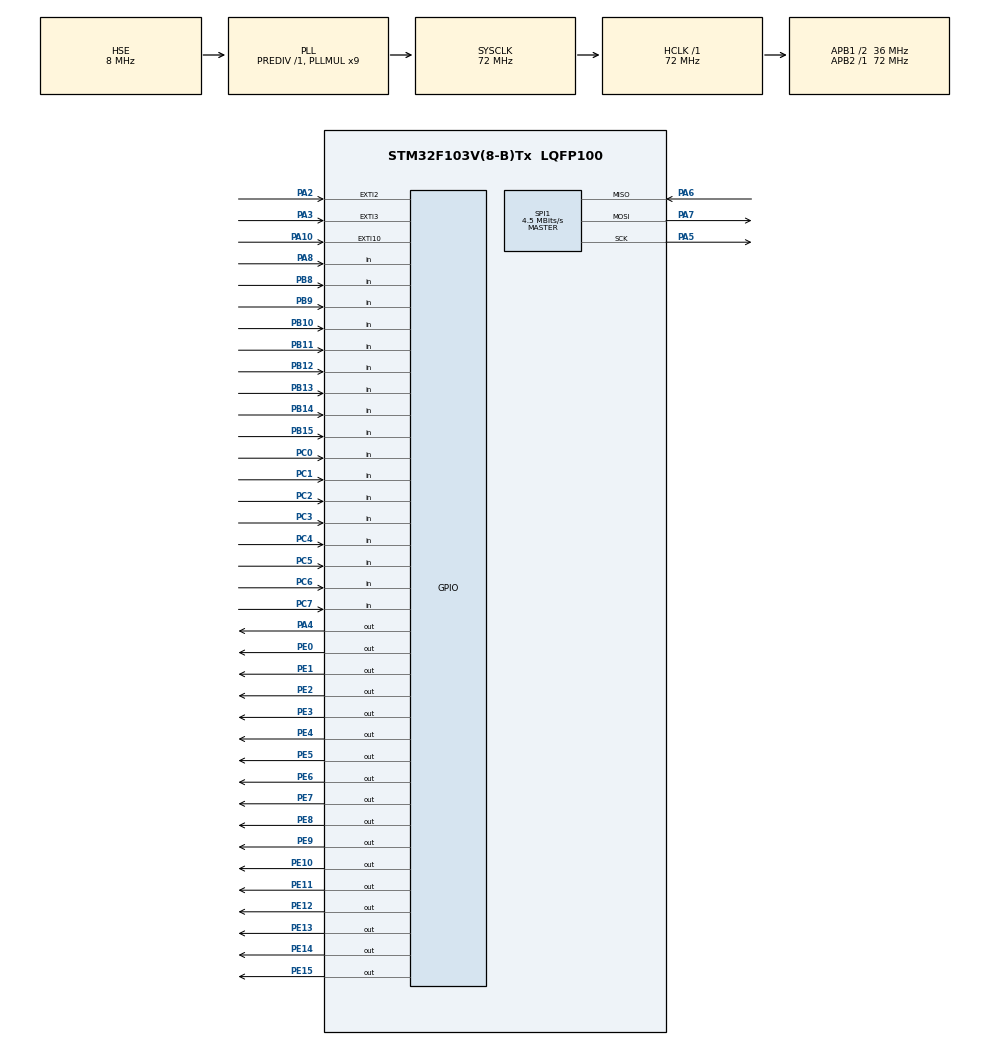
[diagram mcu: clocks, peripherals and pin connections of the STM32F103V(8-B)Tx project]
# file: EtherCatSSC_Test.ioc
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Mcu.Family=STM32F1
Mcu.Name=STM32F103V(8-B)Tx
Mcu.Package=LQFP100
NVIC.PriorityGroup=NVIC_PRIORITYGROUP_4
OSC_IN.Mode=HSE-External-Oscillator
OSC_IN.Signal=RCC_OSC_IN
OSC_OUT.Mode=HSE-External-Oscillator
OSC_OUT.Signal=RCC_OSC_OUT
PA10.Signal=GPXTI10
PA13.Mode=Serial_Wire
PA13.Signal=SYS_JTMS-SWDIO
PA14.Mode=Serial_Wire
PA14.Signal=SYS_JTCK-SWCLK
PA2.Signal=GPXTI2
PA3.Signal=GPXTI3
PA4.GPIO_Speed=GPIO_SPEED_FREQ_HIGH
PA4.PinState=GPIO_PIN_SET
PA4.Signal=GPIO_Output
PA5.Mode=Full_Duplex_Master
PA5.Signal=SPI1_SCK
PA6.Mode=Full_Duplex_Master
PA6.Signal=SPI1_MISO
PA7.Mode=Full_Duplex_Master
PA7.Signal=SPI1_MOSI
PA8.Signal=GPIO_Input
PB10.GPIO_Mode=GPIO_MODE_INPUT
PB10.GPIO_PuPd=GPIO_PULLDOWN
PB10.Signal=GPIO_Input
PB11.GPIO_Mode=GPIO_MODE_INPUT
PB11.GPIO_PuPd=GPIO_PULLDOWN
PB11.Signal=GPIO_Input
PB12.GPIO_Mode=GPIO_MODE_INPUT
PB12.GPIO_PuPd=GPIO_PULLDOWN
PB12.Signal=GPIO_Input
PB13.GPIO_Mode=GPIO_MODE_INPUT
PB13.GPIO_PuPd=GPIO_PULLDOWN
PB13.Signal=GPIO_Input
PB14.GPIO_Mode=GPIO_MODE_INPUT
PB14.GPIO_PuPd=GPIO_PULLDOWN
PB14.Signal=GPIO_Input
PB15.GPIO_Mode=GPIO_MODE_INPUT
PB15.GPIO_PuPd=GPIO_PULLDOWN
PB15.Signal=GPIO_Input
PB8.GPIO_Mode=GPIO_MODE_INPUT
PB8.GPIO_PuPd=GPIO_PULLDOWN
PB8.Signal=GPIO_Input
PB9.GPIO_Mode=GPIO_MODE_INPUT
PB9.GPIO_PuPd=GPIO_PULLDOWN
PB9.Signal=GPIO_Input
PC0.GPIO_Mode=GPIO_MODE_INPUT
PC0.GPIO_PuPd=GPIO_PULLDOWN
PC0.Signal=GPIO_Input
PC1.GPIO_Mode=GPIO_MODE_INPUT
PC1.GPIO_PuPd=GPIO_PULLDOWN
PC1.Signal=GPIO_Input
PC14-OSC32_IN.Mode=LSE-External-Oscillator
PC14-OSC32_IN.Signal=RCC_OSC32_IN
PC15-OSC32_OUT.Mode=LSE-External-Oscillator
PC15-OSC32_OUT.Signal=RCC_OSC32_OUT
PC2.GPIO_Mode=GPIO_MODE_INPUT
PC2.GPIO_PuPd=GPIO_PULLDOWN
PC2.Signal=GPIO_Input
PC3.GPIO_Mode=GPIO_MODE_INPUT
PC3.GPIO_PuPd=GPIO_PULLDOWN
PC3.Signal=GPIO_Input
PC4.GPIO_Mode=GPIO_MODE_INPUT
PC4.GPIO_PuPd=GPIO_PULLDOWN
PC4.Signal=GPIO_Input
PC5.GPIO_Mode=GPIO_MODE_INPUT
PC5.GPIO_PuPd=GPIO_PULLDOWN
PC5.Signal=GPIO_Input
PC6.GPIO_Mode=GPIO_MODE_INPUT
PC6.GPIO_PuPd=GPIO_PULLDOWN
PC6.Signal=GPIO_Input
PC7.GPIO_Mode=GPIO_MODE_INPUT
PC7.GPIO_PuPd=GPIO_PULLDOWN
PC7.Signal=GPIO_Input
PE0.Signal=GPIO_Output
PE1.Signal=GPIO_Output
PE10.Signal=GPIO_Output
PE11.Signal=GPIO_Output
PE12.Signal=GPIO_Output
PE13.Signal=GPIO_Output
PE14.Signal=GPIO_Output
PE15.Signal=GPIO_Output
PE2.Signal=GPIO_Output
PE3.Signal=GPIO_Output
PE4.Signal=GPIO_Output
PE5.Signal=GPIO_Output
PE6.Signal=GPIO_Output
PE7.Signal=GPIO_Output
PE8.Signal=GPIO_Output
PE9.Signal=GPIO_Output
ProjectManager.HeapSize=0x200
ProjectManager.StackSize=0x400
ProjectManager.TargetToolchain=MDK-ARM V5.32
RCC.AHBFreq_Value=72000000
RCC.APB1CLKDivider=RCC_HCLK_DIV2
RCC.APB1Freq_Value=36000000
RCC.APB1TimFreq_Value=72000000
RCC.APB2Freq_Value=72000000
RCC.APB2TimFreq_Value=72000000
RCC.HCLKFreq_Value=72000000
RCC.PLLMUL=RCC_PLL_MUL9
RCC.PLLSourceVirtual=RCC_PLLSOURCE_HSE
RCC.SYSCLKFreq_VALUE=72000000
RCC.SYSCLKSource=RCC_SYSCLKSOURCE_PLLCLK
RCC.USBFreq_Value=72000000
SPI1.BaudRatePrescaler=SPI_BAUDRATEPRESCALER_16
SPI1.CLKPhase=SPI_PHASE_2EDGE
SPI1.CLKPolarity=SPI_POLARITY_HIGH
SPI1.CalculateBaudRate=4.5 MBits/s
SPI1.Direction=SPI_DIRECTION_2LINES
SPI1.Mode=SPI_MODE_MASTER
SPI1.VirtualType=VM_MASTER
board=custom

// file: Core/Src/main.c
/* USER CODE BEGIN Header */
/**
  ******************************************************************************
  * @file           : main.c
  * @brief          : Main program body
  ******************************************************************************
  * @attention
  *
  * Copyright (c) 2026 STMicroelectronics.
  * All rights reserved.
  *
  * This software is licensed under terms that can be found in the LICENSE file
  * in the root directory of this software component.
  * If no LICENSE file comes with this software, it is provided AS-IS.
  *
  ******************************************************************************
  */
/* USER CODE END Header */
#include "main.h"
#include "spi.h"
#include "gpio.h"

/* USER CODE BEGIN Includes */
#include "AX58100.h"
#include "Esc_hw.h"
#include "applInterface.h"
/* USER CODE END Includes */

/* USER CODE BEGIN PD */
#ifndef AX58100_SELF_TEST_ENABLE
#define AX58100_SELF_TEST_ENABLE  0
#endif

/* USER CODE END PD */

void SystemClock_Config(void);

int main(void)
{

  /* MCU Configuration--------------------------------------------------------*/

  /* Reset of all peripherals, Initializes the Flash interface and the Systick. */
  HAL_Init();

  /* Configure the system clock */
  SystemClock_Config();

  /* Initialize all configured peripherals */
  MX_GPIO_Init();
  MX_SPI1_Init();
  /* USER CODE BEGIN 2 */
  // 等待AX58100就绪，否则无法正常进入OP
  if (!AX58100_WaitReady(3000))
  {
      while (1)
      {
          /* AX58100 not ready */
      }
  }

  #if AX58100_SELF_TEST_ENABLE
  AX58100_SelfTest();
  #endif
  MainInit();
  /* USER CODE END 2 */

  /* Infinite loop */
  /* USER CODE BEGIN WHILE */
  while (1)
  {
    MainLoop();
    /* USER CODE END WHILE */

  }
}

void SystemClock_Config(void)
{
  RCC_OscInitTypeDef RCC_OscInitStruct = {0};
  RCC_ClkInitTypeDef RCC_ClkInitStruct = {0};

  /** Initializes the RCC Oscillators according to the specified parameters
  * in the RCC_OscInitTypeDef structure.
  */
  RCC_OscInitStruct.OscillatorType = RCC_OSCILLATORTYPE_HSE;
  RCC_OscInitStruct.HSEState = RCC_HSE_ON;
  RCC_OscInitStruct.HSEPredivValue = RCC_HSE_PREDIV_DIV1;
  RCC_OscInitStruct.HSIState = RCC_HSI_ON;
  RCC_OscInitStruct.PLL.PLLState = RCC_PLL_ON;
  RCC_OscInitStruct.PLL.PLLSource = RCC_PLLSOURCE_HSE;
  RCC_OscInitStruct.PLL.PLLMUL = RCC_PLL_MUL9;
  if (HAL_RCC_OscConfig(&RCC_OscInitStruct) != HAL_OK)
  {
    Error_Handler();
  }

  /** Initializes the CPU, AHB and APB buses clocks
  */
  RCC_ClkInitStruct.ClockType = RCC_CLOCKTYPE_HCLK|RCC_CLOCKTYPE_SYSCLK
                              |RCC_CLOCKTYPE_PCLK1|RCC_CLOCKTYPE_PCLK2;
  RCC_ClkInitStruct.SYSCLKSource = RCC_SYSCLKSOURCE_PLLCLK;
  RCC_ClkInitStruct.AHBCLKDivider = RCC_SYSCLK_DIV1;
  RCC_ClkInitStruct.APB1CLKDivider = RCC_HCLK_DIV2;
  RCC_ClkInitStruct.APB2CLKDivider = RCC_HCLK_DIV1;

  if (HAL_RCC_ClockConfig(&RCC_ClkInitStruct, FLASH_LATENCY_2) != HAL_OK)
  {
    Error_Handler();
  }
}

void Error_Handler(void)
{
  __disable_irq();
  while (1)
  {
  }
}
